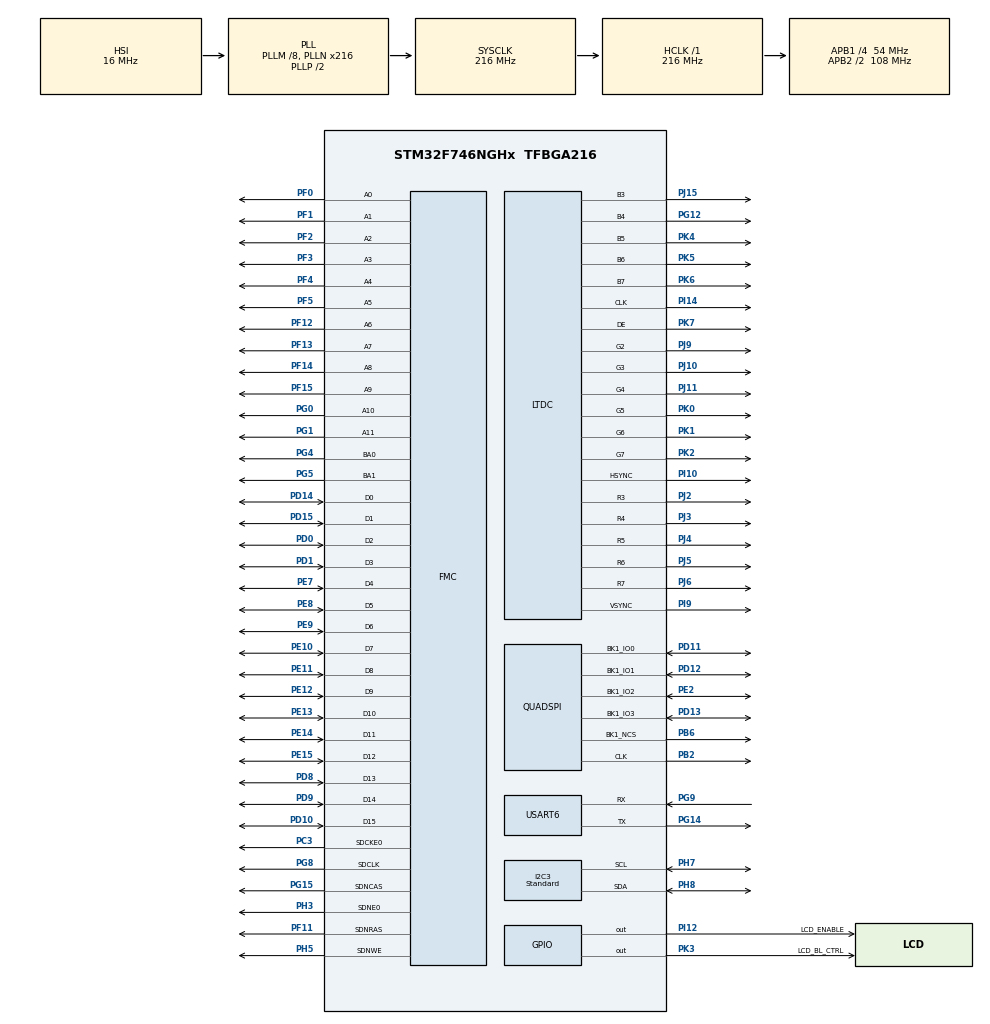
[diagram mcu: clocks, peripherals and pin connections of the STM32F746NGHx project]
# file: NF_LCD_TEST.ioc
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CORTEX_M7.AccessPermission-Cortex_Memory_Protection_Unit_Region1_Settings=MPU_REGION_FULL_ACCESS
CORTEX_M7.BaseAddress-Cortex_Memory_Protection_Unit_Region0_Settings=0xC0000000
CORTEX_M7.BaseAddress-Cortex_Memory_Protection_Unit_Region1_Settings=0xC0000000
CORTEX_M7.CPU_DCache=Enabled
CORTEX_M7.CPU_ICache=Enabled
CORTEX_M7.DisableExec-Cortex_Memory_Protection_Unit_Region0_Settings=MPU_INSTRUCTION_ACCESS_DISABLE
CORTEX_M7.DisableExec-Cortex_Memory_Protection_Unit_Region1_Settings=MPU_INSTRUCTION_ACCESS_DISABLE
CORTEX_M7.Enable-Cortex_Memory_Protection_Unit_Region0_Settings=MPU_REGION_ENABLE
CORTEX_M7.Enable-Cortex_Memory_Protection_Unit_Region1_Settings=MPU_REGION_ENABLE
CORTEX_M7.IsBufferable-Cortex_Memory_Protection_Unit_Region1_Settings=MPU_ACCESS_BUFFERABLE
CORTEX_M7.IsCacheable-Cortex_Memory_Protection_Unit_Region1_Settings=MPU_ACCESS_CACHEABLE
CORTEX_M7.MPU_Control=MPU_PRIVILEGED_DEFAULT
CORTEX_M7.Size-Cortex_Memory_Protection_Unit_Region0_Settings=MPU_REGION_SIZE_512MB
CORTEX_M7.Size-Cortex_Memory_Protection_Unit_Region1_Settings=MPU_REGION_SIZE_8MB
DMA2D.ColorMode=DMA2D_OUTPUT_ARGB8888
FMC.CASLatency1=FMC_SDRAM_CAS_LATENCY_2
FMC.ExitSelfRefreshDelay1=8
FMC.LoadToActiveDelay1=2
FMC.RCDDelay1=2
FMC.RPDelay1=2
FMC.ReadPipeDelay1=FMC_SDRAM_RPIPE_DELAY_2
FMC.RowCycleDelay1=7
FMC.SDClockPeriod1=FMC_SDRAM_CLOCK_PERIOD_2
FMC.SelfRefreshTime1=5
FMC.WriteRecoveryTime1=3
FREERTOS.Tasks01=defaultTask,0,128,StartDefaultTask,Default,NULL,Dynamic,NULL,NULL
FREERTOS.configTOTAL_HEAP_SIZE=65536
FREERTOS.configUSE_NEWLIB_REENTRANT=1
I2C3.I2C_Speed_Mode=I2C_Standard
I2C3.Timing=0x20404768
LTDC.ActiveH=272
LTDC.ActiveW=480
LTDC.Alpha_L0=255
LTDC.FBStartAdress_L0=0xC0000000
LTDC.FBStartAdress_L1=0xC03F8000
LTDC.HBP=13
LTDC.HFP=32
LTDC.HSync=41
LTDC.ImageHeight_L0=272
LTDC.ImageWidth_L0=480
LTDC.ImageWidth_L1=480
LTDC.Layers=0
LTDC.PixelFormat_L0=LTDC_PIXEL_FORMAT_ARGB8888
LTDC.VSync=10
LTDC.WindowX0_L0=0
LTDC.WindowX1_L0=480
LTDC.WindowY1_L0=272
Mcu.Family=STM32F7
Mcu.Name=STM32F746NGHx
Mcu.Package=TFBGA216
NVIC.DMA2D_IRQn=true\:5\:0\:false\:false\:true\:true\:true\:true\:true
NVIC.I2C3_EV_IRQn=true\:5\:0\:false\:false\:true\:true\:true\:true\:true
NVIC.LTDC_IRQn=true\:5\:0\:false\:false\:true\:true\:true\:true\:true
NVIC.PriorityGroup=NVIC_PRIORITYGROUP_4
NVIC.TIM6_DAC_IRQn=true\:15\:0\:false\:false\:true\:false\:false\:true\:true
NVIC.TimeBase=TIM6_DAC_IRQn
NVIC.TimeBaseIP=TIM6
PB2.Mode=Single Bank 1
PB2.Signal=QUADSPI_CLK
PB6.Mode=Single Bank 1
PB6.Signal=QUADSPI_BK1_NCS
PC3.Mode=SdramChipSelect1_1
PC3.Signal=FMC_SDCKE0
PD0.Signal=FMC_D2_DA2
PD1.Signal=FMC_D3_DA3
PD10.Signal=FMC_D15_DA15
PD11.Mode=Single Bank 1
PD11.Signal=QUADSPI_BK1_IO0
PD12.Mode=Single Bank 1
PD12.Signal=QUADSPI_BK1_IO1
PD13.Mode=Single Bank 1
PD13.Signal=QUADSPI_BK1_IO3
PD14.Signal=FMC_D0_DA0
PD15.Signal=FMC_D1_DA1
PD8.Signal=FMC_D13_DA13
PD9.Signal=FMC_D14_DA14
PE10.Signal=FMC_D7_DA7
PE11.Signal=FMC_D8_DA8
PE12.Signal=FMC_D9_DA9
PE13.Signal=FMC_D10_DA10
PE14.Signal=FMC_D11_DA11
PE15.Signal=FMC_D12_DA12
PE2.Mode=Single Bank 1
PE2.Signal=QUADSPI_BK1_IO2
PE7.Signal=FMC_D4_DA4
PE8.Signal=FMC_D5_DA5
PE9.Signal=FMC_D6_DA6
PF0.Signal=FMC_A0
PF1.Signal=FMC_A1
PF11.Signal=FMC_SDNRAS
PF12.Signal=FMC_A6
PF13.Signal=FMC_A7
PF14.Signal=FMC_A8
PF15.Signal=FMC_A9
PF2.Signal=FMC_A2
PF3.Signal=FMC_A3
PF4.Signal=FMC_A4
PF5.Signal=FMC_A5
PG0.Signal=FMC_A10
PG1.Signal=FMC_A11
PG12.Mode=RGB565
PG12.Signal=LTDC_B4
PG14.Mode=Asynchronous
PG14.Signal=USART6_TX
PG15.Signal=FMC_SDNCAS
PG4.Signal=FMC_A14_BA0
PG5.Signal=FMC_A15_BA1
PG8.Signal=FMC_SDCLK
PG9.Mode=Asynchronous
PG9.Signal=USART6_RX
PH0/OSC_IN.Mode=HSE-External-Oscillator
PH0/OSC_IN.Signal=RCC_OSC_IN
PH1/OSC_OUT.Mode=HSE-External-Oscillator
PH1/OSC_OUT.Signal=RCC_OSC_OUT
PH3.Mode=SdramChipSelect1_1
PH3.Signal=FMC_SDNE0
PH5.Signal=FMC_SDNWE
PH7.Mode=I2C
PH7.Signal=I2C3_SCL
PH8.Mode=I2C
PH8.Signal=I2C3_SDA
PI10.Mode=RGB565
PI10.Signal=LTDC_HSYNC
PI12.GPIO_Label=LCD_ENABLE
PI12.PinState=GPIO_PIN_SET
PI12.Signal=GPIO_Output
PI14.Mode=RGB565
PI14.Signal=LTDC_CLK
PI15.Signal=LTDC_R0
PI9.Mode=RGB565
PI9.Signal=LTDC_VSYNC
PJ0.Signal=LTDC_R1
PJ1.Signal=LTDC_R2
PJ10.Mode=RGB565
PJ10.Signal=LTDC_G3
PJ11.Mode=RGB565
PJ11.Signal=LTDC_G4
PJ14.Signal=LTDC_B2
PJ15.Mode=RGB565
PJ15.Signal=LTDC_B3
PJ2.Mode=RGB565
PJ2.Signal=LTDC_R3
PJ3.Mode=RGB565
PJ3.Signal=LTDC_R4
PJ4.Mode=RGB565
PJ4.Signal=LTDC_R5
PJ5.Mode=RGB565
PJ5.Signal=LTDC_R6
PJ6.Mode=RGB565
PJ6.Signal=LTDC_R7
PJ7.Signal=LTDC_G0
PJ8.Signal=LTDC_G1
PJ9.Mode=RGB565
PJ9.Signal=LTDC_G2
PK0.Mode=RGB565
PK0.Signal=LTDC_G5
PK1.Mode=RGB565
PK1.Signal=LTDC_G6
PK2.Mode=RGB565
PK2.Signal=LTDC_G7
PK3.GPIO_Label=LCD_BL_CTRL
PK3.PinState=GPIO_PIN_SET
PK3.Signal=GPIO_Output
PK4.Mode=RGB565
PK4.Signal=LTDC_B5
PK5.Mode=RGB565
PK5.Signal=LTDC_B6
PK6.Mode=RGB565
PK6.Signal=LTDC_B7
PK7.Mode=RGB565
PK7.Signal=LTDC_DE
ProjectManager.HeapSize=0x200
ProjectManager.StackSize=0x400
ProjectManager.TargetToolchain=STM32CubeIDE
QUADSPI.ChipSelectHighTime=QSPI_CS_HIGH_TIME_6_CYCLE
QUADSPI.ClockPrescaler=2
QUADSPI.FifoThreshold=4
QUADSPI.FlashSize=23
QUADSPI.SampleShifting=QSPI_SAMPLE_SHIFTING_HALFCYCLE
RCC.AHBFreq_Value=216000000
RCC.APB1CLKDivider=RCC_HCLK_DIV4
RCC.APB1Freq_Value=54000000
RCC.APB1TimFreq_Value=108000000
RCC.APB2CLKDivider=RCC_HCLK_DIV2
RCC.APB2Freq_Value=108000000
RCC.APB2TimFreq_Value=216000000
RCC.CortexFreq_Value=216000000
RCC.HCLKFreq_Value=216000000
RCC.HSE_VALUE=25000000
RCC.HSI_VALUE=16000000
RCC.LSE_VALUE=32768
RCC.PLLM=8
RCC.PLLN=216
RCC.PLLSAIN=50
RCC.PLLSAIR=5
RCC.PLLSourceVirtual=RCC_PLLSOURCE_HSI
RCC.SYSCLKFreq_VALUE=216000000
RCC.SYSCLKSource=RCC_SYSCLKSOURCE_PLLCLK
RCC.USBFreq_Value=216000000
RCC.VCOOutputFreq_Value=432000000
SH.FMC_A0.0=FMC_A0,12b-sda1
SH.FMC_A1.0=FMC_A1,12b-sda1
SH.FMC_A10.0=FMC_A10,12b-sda1
SH.FMC_A11.0=FMC_A11,12b-sda1
SH.FMC_A14_BA0.0=FMC_BA0,FourSdramBanks1
SH.FMC_A15_BA1.0=FMC_BA1,FourSdramBanks1
SH.FMC_A2.0=FMC_A2,12b-sda1
SH.FMC_A3.0=FMC_A3,12b-sda1
SH.FMC_A4.0=FMC_A4,12b-sda1
SH.FMC_A5.0=FMC_A5,12b-sda1
SH.FMC_A6.0=FMC_A6,12b-sda1
SH.FMC_A7.0=FMC_A7,12b-sda1
SH.FMC_A8.0=FMC_A8,12b-sda1
SH.FMC_A9.0=FMC_A9,12b-sda1
SH.FMC_D0_DA0.0=FMC_D0,sd-16b-d1
SH.FMC_D10_DA10.0=FMC_D10,sd-16b-d1
SH.FMC_D11_DA11.0=FMC_D11,sd-16b-d1
SH.FMC_D12_DA12.0=FMC_D12,sd-16b-d1
SH.FMC_D13_DA13.0=FMC_D13,sd-16b-d1
SH.FMC_D14_DA14.0=FMC_D14,sd-16b-d1
SH.FMC_D15_DA15.0=FMC_D15,sd-16b-d1
SH.FMC_D1_DA1.0=FMC_D1,sd-16b-d1
SH.FMC_D2_DA2.0=FMC_D2,sd-16b-d1
SH.FMC_D3_DA3.0=FMC_D3,sd-16b-d1
SH.FMC_D4_DA4.0=FMC_D4,sd-16b-d1
SH.FMC_D5_DA5.0=FMC_D5,sd-16b-d1
SH.FMC_D6_DA6.0=FMC_D6,sd-16b-d1
SH.FMC_D7_DA7.0=FMC_D7,sd-16b-d1
SH.FMC_D8_DA8.0=FMC_D8,sd-16b-d1
SH.FMC_D9_DA9.0=FMC_D9,sd-16b-d1
SH.FMC_SDCLK.0=FMC_SDCLK,12b-sda1
SH.FMC_SDNCAS.0=FMC_SDNCAS,12b-sda1
SH.FMC_SDNRAS.0=FMC_SDNRAS,12b-sda1
SH.FMC_SDNWE.0=FMC_SDNWE,12b-sda1
STMicroelectronics.X-CUBE-TOUCHGFX.4.22.0.tgfx_address1=0xC0010000
STMicroelectronics.X-CUBE-TOUCHGFX.4.22.0.tgfx_address2=0xC006FA00
STMicroelectronics.X-CUBE-TOUCHGFX.4.22.0.tgfx_buffering_strategy=Double
STMicroelectronics.X-CUBE-TOUCHGFX.4.22.0.tgfx_display_interface=disp_ltdc
STMicroelectronics.X-CUBE-TOUCHGFX.4.22.0.tgfx_hardware_accelerator=dma_2d
STMicroelectronics.X-CUBE-TOUCHGFX.4.22.0.tgfx_location=By Address
STMicroelectronics.X-CUBE-TOUCHGFX.4.22.0.tgfx_vsync=vsync_ltdc
STMicroelectronics.X-CUBE-TOUCHGFX.4.22.0_IsPackSelfContextualization=true
USART6.StopBits=STOPBITS_1
USART6.VirtualMode-Asynchronous=VM_ASYNC
VP_CRC_VS_CRC.Mode=CRC_Activate
VP_DMA2D_VS_DMA2D.Mode=DMA2D_Activate
VP_FREERTOS_VS_CMSIS_V1.Mode=CMSIS_V1
VP_SYS_VS_tim6.Mode=TIM6
board=STM32F746G-DISCO

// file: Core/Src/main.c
/* USER CODE BEGIN Header */
/**
  ******************************************************************************
  * @file           : main.c
  * @brief          : Main program body
  ******************************************************************************
  * @attention
  *
  * Copyright (c) 2023 STMicroelectronics.
  * All rights reserved.
  *
  * This software is licensed under terms that can be found in the LICENSE file
  * in the root directory of this software component.
  * If no LICENSE file comes with this software, it is provided AS-IS.
  *
  ******************************************************************************
  */
/* USER CODE END Header */
#include "main.h"
#include "cmsis_os.h"
#include "crc.h"
#include "dma2d.h"
#include "i2c.h"
#include "ltdc.h"
#include "quadspi.h"
#include "usart.h"
#include "gpio.h"
#include "fmc.h"

/* USER CODE BEGIN Includes */
#include "lvgl/lvgl.h"
#include "lvgl/demos/lv_demos.h"
#include "lvgl_port_touch.h"
#include "lvgl_port_display.h"
#include "UI/ui.h"
/* USER CODE END Includes */

void SystemClock_Config(void);
static void MPU_Initialize(void);
static void MPU_Config(void);
void MX_FREERTOS_Init(void);

int main(void)
{

  /* Enable I-Cache---------------------------------------------------------*/
  SCB_EnableICache();

  /* Enable D-Cache---------------------------------------------------------*/
  SCB_EnableDCache();

  /* MCU Configuration--------------------------------------------------------*/

  /* Reset of all peripherals, Initializes the Flash interface and the Systick. */
  HAL_Init();

  /* MPU Configuration--------------------------------------------------------*/
  MPU_Config();

  /* Configure the system clock */
  SystemClock_Config();

  /* Initialize all configured peripherals */
  MX_GPIO_Init();
  MX_DMA2D_Init();
  MX_CRC_Init();
  MX_LTDC_Init();
  MX_FMC_Init();
  MX_I2C3_Init();
  MX_USART6_UART_Init();
  MX_QUADSPI_Init();
  /* USER CODE BEGIN 2 */

  /* initialize LVGL framework */
  lv_init();

  /* initialize display and touchscreen */
  lvgl_display_init();
  lvgl_touchscreen_init();

  ui_init();

  /* lvgl demo */
//  lv_demo_benchmark();
//  lv_demo_widgets();
//  lv_demo_music();
//  lvgl_test();

  /* USER CODE END 2 */

  /* Call init function for freertos objects (in freertos.c) */
  MX_FREERTOS_Init();

  /* Start scheduler */
  osKernelStart();

  /* We should never get here as control is now taken by the scheduler */
  /* Infinite loop */
  while (1)
  {

  }
}

void SystemClock_Config(void)
{
  RCC_OscInitTypeDef RCC_OscInitStruct = {0};
  RCC_ClkInitTypeDef RCC_ClkInitStruct = {0};

  /** Configure the main internal regulator output voltage
  */
  __HAL_RCC_PWR_CLK_ENABLE();
  __HAL_PWR_VOLTAGESCALING_CONFIG(PWR_REGULATOR_VOLTAGE_SCALE1);

  /** Initializes the RCC Oscillators according to the specified parameters
  * in the RCC_OscInitTypeDef structure.
  */
  RCC_OscInitStruct.OscillatorType = RCC_OSCILLATORTYPE_HSI;
  RCC_OscInitStruct.HSIState = RCC_HSI_ON;
  RCC_OscInitStruct.HSICalibrationValue = RCC_HSICALIBRATION_DEFAULT;
  RCC_OscInitStruct.PLL.PLLState = RCC_PLL_ON;
  RCC_OscInitStruct.PLL.PLLSource = RCC_PLLSOURCE_HSI;
  RCC_OscInitStruct.PLL.PLLM = 8;
  RCC_OscInitStruct.PLL.PLLN = 216;
  RCC_OscInitStruct.PLL.PLLP = RCC_PLLP_DIV2;
  RCC_OscInitStruct.PLL.PLLQ = 2;
  if (HAL_RCC_OscConfig(&RCC_OscInitStruct) != HAL_OK)
  {
    Error_Handler();
  }

  /** Activate the Over-Drive mode
  */
  if (HAL_PWREx_EnableOverDrive() != HAL_OK)
  {
    Error_Handler();
  }

  /** Initializes the CPU, AHB and APB buses clocks
  */
  RCC_ClkInitStruct.ClockType = RCC_CLOCKTYPE_HCLK|RCC_CLOCKTYPE_SYSCLK
                              |RCC_CLOCKTYPE_PCLK1|RCC_CLOCKTYPE_PCLK2;
  RCC_ClkInitStruct.SYSCLKSource = RCC_SYSCLKSOURCE_PLLCLK;
  RCC_ClkInitStruct.AHBCLKDivider = RCC_SYSCLK_DIV1;
  RCC_ClkInitStruct.APB1CLKDivider = RCC_HCLK_DIV4;
  RCC_ClkInitStruct.APB2CLKDivider = RCC_HCLK_DIV2;

  if (HAL_RCC_ClockConfig(&RCC_ClkInitStruct, FLASH_LATENCY_7) != HAL_OK)
  {
    Error_Handler();
  }
}

/* MPU Configuration */

void MPU_Config(void)
{
  MPU_Region_InitTypeDef MPU_InitStruct = {0};

  /* Disables the MPU */
  HAL_MPU_Disable();

  /** Initializes and configures the Region and the memory to be protected
  */
  MPU_InitStruct.Enable = MPU_REGION_ENABLE;
  MPU_InitStruct.Number = MPU_REGION_NUMBER0;
  MPU_InitStruct.BaseAddress = 0xC0000000;
  MPU_InitStruct.Size = MPU_REGION_SIZE_512MB;
  MPU_InitStruct.SubRegionDisable = 0x0;
  MPU_InitStruct.TypeExtField = MPU_TEX_LEVEL0;
  MPU_InitStruct.AccessPermission = MPU_REGION_NO_ACCESS;
  MPU_InitStruct.DisableExec = MPU_INSTRUCTION_ACCESS_DISABLE;
  MPU_InitStruct.IsShareable = MPU_ACCESS_NOT_SHAREABLE;
  MPU_InitStruct.IsCacheable = MPU_ACCESS_NOT_CACHEABLE;
  MPU_InitStruct.IsBufferable = MPU_ACCESS_NOT_BUFFERABLE;

  HAL_MPU_ConfigRegion(&MPU_InitStruct);

  /** Initializes and configures the Region and the memory to be protected
  */
  MPU_InitStruct.Number = MPU_REGION_NUMBER1;
  MPU_InitStruct.Size = MPU_REGION_SIZE_8MB;
  MPU_InitStruct.AccessPermission = MPU_REGION_FULL_ACCESS;
  MPU_InitStruct.IsCacheable = MPU_ACCESS_CACHEABLE;
  MPU_InitStruct.IsBufferable = MPU_ACCESS_BUFFERABLE;

  HAL_MPU_ConfigRegion(&MPU_InitStruct);
  /* Enables the MPU */
  HAL_MPU_Enable(MPU_PRIVILEGED_DEFAULT);

}

void HAL_TIM_PeriodElapsedCallback(TIM_HandleTypeDef *htim)
{
  if (htim->Instance == TIM6) {
    HAL_IncTick();
  }
}

void Error_Handler(void)
{
  __disable_irq();
  while (1)
  {
  }
}

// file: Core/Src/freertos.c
/* USER CODE BEGIN Header */
/**
  ******************************************************************************
  * File Name          : freertos.c
  * Description        : Code for freertos applications
  ******************************************************************************
  * @attention
  *
  * Copyright (c) 2023 STMicroelectronics.
  * All rights reserved.
  *
  * This software is licensed under terms that can be found in the LICENSE file
  * in the root directory of this software component.
  * If no LICENSE file comes with this software, it is provided AS-IS.
  *
  ******************************************************************************
  */
/* USER CODE END Header */

#include "FreeRTOS.h"
#include "task.h"
#include "main.h"
#include "cmsis_os.h"

/* USER CODE BEGIN Includes */
//#include "app_touchgfx.h"
#include "lvgl/lvgl.h"
/* USER CODE END Includes */

osThreadId defaultTaskHandle;

/* USER CODE BEGIN FunctionPrototypes */
osThreadId lvglTickHandle;
osThreadId lvglTimerHandle;

void LVGLTimer(void const * argument);
void LVGLTick(void const * argument);
/* USER CODE END FunctionPrototypes */

void StartDefaultTask(void const * argument);

void MX_FREERTOS_Init(void); /* (MISRA C 2004 rule 8.1) */

/* GetIdleTaskMemory prototype (linked to static allocation support) */
void vApplicationGetIdleTaskMemory( StaticTask_t **ppxIdleTaskTCBBuffer, StackType_t **ppxIdleTaskStackBuffer, uint32_t *pulIdleTaskStackSize );

/* USER CODE BEGIN GET_IDLE_TASK_MEMORY */
static StaticTask_t xIdleTaskTCBBuffer;
static StackType_t xIdleStack[configMINIMAL_STACK_SIZE];

void vApplicationGetIdleTaskMemory( StaticTask_t **ppxIdleTaskTCBBuffer, StackType_t **ppxIdleTaskStackBuffer, uint32_t *pulIdleTaskStackSize )
{
  *ppxIdleTaskTCBBuffer = &xIdleTaskTCBBuffer;
  *ppxIdleTaskStackBuffer = &xIdleStack[0];
  *pulIdleTaskStackSize = configMINIMAL_STACK_SIZE;
  /* place for user code */
}
/* USER CODE END GET_IDLE_TASK_MEMORY */

void MX_FREERTOS_Init(void) {

  /* Create the thread(s) */
  /* definition and creation of defaultTask */
  osThreadDef(defaultTask, StartDefaultTask, osPriorityNormal, 0, 128);
  defaultTaskHandle = osThreadCreate(osThread(defaultTask), NULL);

  /* USER CODE BEGIN RTOS_THREADS */
  /* add threads, ... */
  osThreadDef(lvglTick, LVGLTick, osPriorityNormal, 0, 4*1024);
  lvglTickHandle = osThreadCreate(osThread(lvglTick), NULL);

  osThreadDef(lvglTimer, LVGLTimer, osPriorityNormal, 0, 4*1024);
  lvglTimerHandle = osThreadCreate(osThread(lvglTimer), NULL);
  /* USER CODE END RTOS_THREADS */

}

void StartDefaultTask(void const * argument)
{
  for(;;)
  {
    osDelay(1);
  }
}

/* USER CODE BEGIN Application */
void LVGLTimer(void const * argument)
{
  for(;;)
  {
    lv_timer_handler();
//    osDelay(1);
  }
}
/* LVGL tick source */
void LVGLTick(void const * argument)
{
  for(;;)
  {
    lv_tick_inc(5);
    osDelay(5);
  }
}
/* USER CODE END Application */
